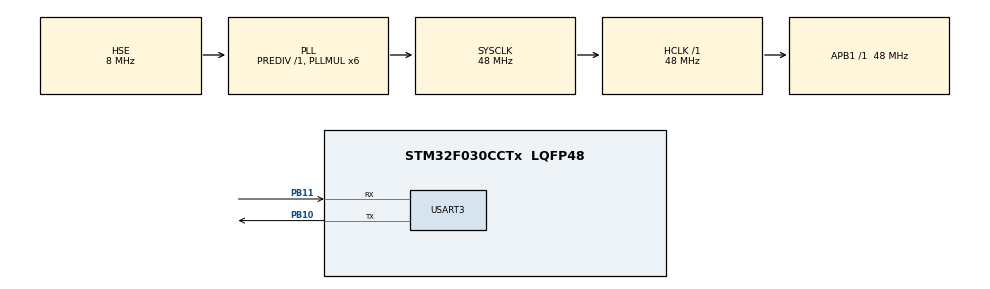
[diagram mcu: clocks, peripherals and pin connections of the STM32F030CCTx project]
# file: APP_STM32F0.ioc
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Mcu.Family=STM32F0
Mcu.Name=STM32F030CCTx
Mcu.Package=LQFP48
NVIC.USART3_6_IRQn=true\:0\:0\:false\:false\:true\:true
PA13.Mode=Serial_Wire
PA13.Signal=SYS_SWDIO
PA14.Mode=Serial_Wire
PA14.Signal=SYS_SWCLK
PB10.Mode=Asynchronous
PB10.Signal=USART3_TX
PB11.Mode=Asynchronous
PB11.Signal=USART3_RX
PF0-OSC_IN.Mode=HSE-External-Oscillator
PF0-OSC_IN.Signal=RCC_OSC_IN
PF1-OSC_OUT.Mode=HSE-External-Oscillator
PF1-OSC_OUT.Signal=RCC_OSC_OUT
ProjectManager.HeapSize=0x200
ProjectManager.StackSize=0x400
ProjectManager.TargetToolchain=MDK-ARM V5
RCC.AHBFreq_Value=48000000
RCC.APB1Freq_Value=48000000
RCC.APB1TimFreq_Value=48000000
RCC.HCLKFreq_Value=48000000
RCC.PLLMUL=RCC_PLL_MUL6
RCC.PLLSourceVirtual=RCC_PLLSOURCE_HSE
RCC.SYSCLKFreq_VALUE=48000000
RCC.SYSCLKSource=RCC_SYSCLKSOURCE_PLLCLK
USART3.VirtualMode-Asynchronous=VM_ASYNC
USART3.WordLength=WORDLENGTH_8B
board=APP_STM32F0

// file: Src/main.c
/**
  ******************************************************************************
  * @file           : main.c
  * @brief          : Main program body
  ******************************************************************************
  ** This notice applies to any and all portions of this file
  * that are not between comment pairs USER CODE BEGIN and
  * USER CODE END. Other portions of this file, whether
  * inserted by the user or by software development tools
  * are owned by their respective copyright owners.
  *
  * COPYRIGHT(c) 2018 STMicroelectronics
  *
  * Redistribution and use in source and binary forms, with or without modification,
  * are permitted provided that the following conditions are met:
  *   1. Redistributions of source code must retain the above copyright notice,
  *      this list of conditions and the following disclaimer.
  *   2. Redistributions in binary form must reproduce the above copyright notice,
  *      this list of conditions and the following disclaimer in the documentation
  *      and/or other materials provided with the distribution.
  *   3. Neither the name of STMicroelectronics nor the names of its contributors
  *      may be used to endorse or promote products derived from this software
  *      without specific prior written permission.
  *
  * THIS SOFTWARE IS PROVIDED BY THE COPYRIGHT HOLDERS AND CONTRIBUTORS "AS IS"
  * AND ANY EXPRESS OR IMPLIED WARRANTIES, INCLUDING, BUT NOT LIMITED TO, THE
  * IMPLIED WARRANTIES OF MERCHANTABILITY AND FITNESS FOR A PARTICULAR PURPOSE ARE
  * DISCLAIMED. IN NO EVENT SHALL THE COPYRIGHT HOLDER OR CONTRIBUTORS BE LIABLE
  * FOR ANY DIRECT, INDIRECT, INCIDENTAL, SPECIAL, EXEMPLARY, OR CONSEQUENTIAL
  * DAMAGES (INCLUDING, BUT NOT LIMITED TO, PROCUREMENT OF SUBSTITUTE GOODS OR
  * SERVICES; LOSS OF USE, DATA, OR PROFITS; OR BUSINESS INTERRUPTION) HOWEVER
  * CAUSED AND ON ANY THEORY OF LIABILITY, WHETHER IN CONTRACT, STRICT LIABILITY,
  * OR TORT (INCLUDING NEGLIGENCE OR OTHERWISE) ARISING IN ANY WAY OUT OF THE USE
  * OF THIS SOFTWARE, EVEN IF ADVISED OF THE POSSIBILITY OF SUCH DAMAGE.
  *
  ******************************************************************************
  */
#include "main.h"
#include "stm32f0xx_hal.h"
#include "usart.h"
#include "gpio.h"

/* USER CODE BEGIN Includes */
#include "umain.h"
#include "printf.h"
#include "uFlash.h"
/* USER CODE END Includes */

/* USER CODE BEGIN PV */
/* Private variables ---------------------------------------------------------*/
#define APPLICATION_ADDRESS     (uint32_t)0x08003800
__IO uint32_t VectorTable[48] __attribute__((section(".RAMVectorTable")));

volatile uint8_t flagUART=0;
volatile uint8_t  ch=0;

/* USER CODE END PV */

void SystemClock_Config(void);

/* USER CODE BEGIN PFP */
/* Private function prototypes -----------------------------------------------*/

/* USER CODE END PFP */

/* USER CODE BEGIN 0 */
void Map(void)
{
    uint32_t mTmp = 0;

    for(mTmp = 0; mTmp < 48; mTmp++)
    {
        VectorTable[mTmp] = *(__IO uint32_t*)((uint32_t)APPLICATION_ADDRESS + (mTmp << 2));
    }

    __HAL_RCC_AHB_FORCE_RESET();

    __HAL_RCC_SYSCFG_CLK_ENABLE();

    __HAL_RCC_AHB_RELEASE_RESET();

    __HAL_SYSCFG_REMAPMEMORY_SRAM();
}

/* USER CODE END 0 */

int main(void)
{
  /* USER CODE BEGIN 1 */
	uint32_t i = 0;
	uint32_t dem=0,dem1=0;
  /* USER CODE END 1 */

  /* MCU Configuration----------------------------------------------------------*/

  /* Reset of all peripherals, Initializes the Flash interface and the Systick. */
  HAL_Init();

  /* USER CODE BEGIN Init */

	Map();

  /* USER CODE END Init */

  /* Configure the system clock */
  SystemClock_Config();

  /* Initialize all configured peripherals */
  MX_GPIO_Init();
  MX_USART3_UART_Init();
  /* USER CODE BEGIN 2 */

	TRACE_DEBUG("\r\n\r\n********** This is Applicaton code **********\n\r");
	TRACE_DEBUG("\r\n\r\n********** Version 5.0 Ngay 26/06/2017 **********\n\r");
	TRACE_DEBUG("\r\n\r\n********** Demo Full system UART **********\n\r");
	TRACE_DEBUG("Waiting character Enter:\n\r");
	TRACE_DEBUG("- '1': Load Main code\r\n");
	TRACE_DEBUG("- '2': Load Logo Production\r\n");
	TRACE_DEBUG("- '3': Load Logo Customer\r\n");
	__HAL_UART_ENABLE_IT(&huart3,UART_IT_RXNE);

	WriteEpromFlash(EepromFlashAddress,HAVE_APP_CODE_ADDR,1);
  /* USER CODE END 2 */

  /* Infinite loop */
  while (1)
  {

  /* USER CODE BEGIN 3 */
	if(flagUART==1) {
			flagUART=0;
			switch(ch) {
				case '1':
					TRACE_DEBUG("\r\n\r\n*****Load Main Code*****: %c\n\r",ch);
					WriteEpromFlash(EepromFlashAddress,RUN_CODE_ADDR,MARK_RUN_BOOT_CODE);

					WriteEpromFlash(EepromFlashAddress,SUCCESS_MAIN_ADDR,0);
					WriteEpromFlash(EepromFlashAddress,SUCCESS_BKUP_ADDR,1);
					NVIC_SystemReset();
					break;
				case '2':
					TRACE_DEBUG("\r\n\r\n***** Load Logo Production *****\n\r");
					break;
				case '3':
					TRACE_DEBUG("\r\n\r\n***** Load Logo Customer *****\n\r");
					break;
				default:
					TRACE_DEBUG("\r\n\r\n***** Enter Other Character*****\n\r");
					ch='\0';
					break;
			}
		}
  }
  /* USER CODE END 3 */

}

void SystemClock_Config(void)
{

  RCC_OscInitTypeDef RCC_OscInitStruct;
  RCC_ClkInitTypeDef RCC_ClkInitStruct;

    /**Initializes the CPU, AHB and APB busses clocks
    */
  RCC_OscInitStruct.OscillatorType = RCC_OSCILLATORTYPE_HSE;
  RCC_OscInitStruct.HSEState = RCC_HSE_ON;
  RCC_OscInitStruct.PLL.PLLState = RCC_PLL_ON;
  RCC_OscInitStruct.PLL.PLLSource = RCC_PLLSOURCE_HSE;
  RCC_OscInitStruct.PLL.PLLMUL = RCC_PLL_MUL6;
  RCC_OscInitStruct.PLL.PREDIV = RCC_PREDIV_DIV1;
  if (HAL_RCC_OscConfig(&RCC_OscInitStruct) != HAL_OK)
  {
    _Error_Handler(__FILE__, __LINE__);
  }

    /**Initializes the CPU, AHB and APB busses clocks
    */
  RCC_ClkInitStruct.ClockType = RCC_CLOCKTYPE_HCLK|RCC_CLOCKTYPE_SYSCLK
                              |RCC_CLOCKTYPE_PCLK1;
  RCC_ClkInitStruct.SYSCLKSource = RCC_SYSCLKSOURCE_PLLCLK;
  RCC_ClkInitStruct.AHBCLKDivider = RCC_SYSCLK_DIV1;
  RCC_ClkInitStruct.APB1CLKDivider = RCC_HCLK_DIV1;

  if (HAL_RCC_ClockConfig(&RCC_ClkInitStruct, FLASH_LATENCY_1) != HAL_OK)
  {
    _Error_Handler(__FILE__, __LINE__);
  }

    /**Configure the Systick interrupt time
    */
  HAL_SYSTICK_Config(HAL_RCC_GetHCLKFreq()/1000);

    /**Configure the Systick
    */
  HAL_SYSTICK_CLKSourceConfig(SYSTICK_CLKSOURCE_HCLK);

  /* SysTick_IRQn interrupt configuration */
  HAL_NVIC_SetPriority(SysTick_IRQn, 0, 0);
}

void _Error_Handler(char *file, int line)
{
  while(1)
  {
  }
}

/************************ (C) COPYRIGHT STMicroelectronics *****END OF FILE****/
